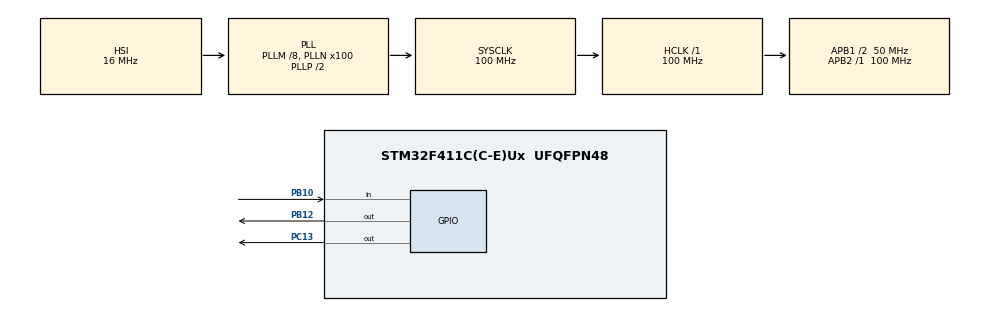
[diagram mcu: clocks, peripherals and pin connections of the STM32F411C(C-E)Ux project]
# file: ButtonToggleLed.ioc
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Mcu.Family=STM32F4
Mcu.Name=STM32F411C(C-E)Ux
Mcu.Package=UFQFPN48
NVIC.PriorityGroup=NVIC_PRIORITYGROUP_4
PA13.Mode=Serial_Wire
PA13.Signal=SYS_JTMS-SWDIO
PA14.Mode=Serial_Wire
PA14.Signal=SYS_JTCK-SWCLK
PB10.GPIO_PuPd=GPIO_PULLDOWN
PB10.Signal=GPIO_Input
PB12.Signal=GPIO_Output
PC13-ANTI_TAMP.Signal=GPIO_Output
PH0\ -\ OSC_IN.Mode=HSE-External-Oscillator
PH0\ -\ OSC_IN.Signal=RCC_OSC_IN
PH1\ -\ OSC_OUT.Mode=HSE-External-Oscillator
PH1\ -\ OSC_OUT.Signal=RCC_OSC_OUT
ProjectManager.HeapSize=0x200
ProjectManager.StackSize=0x400
ProjectManager.TargetToolchain=STM32CubeIDE
RCC.48MHZClocksFreq_Value=50000000
RCC.AHBFreq_Value=100000000
RCC.APB1CLKDivider=RCC_HCLK_DIV2
RCC.APB1Freq_Value=50000000
RCC.APB1TimFreq_Value=100000000
RCC.APB2Freq_Value=100000000
RCC.APB2TimFreq_Value=100000000
RCC.CortexFreq_Value=100000000
RCC.HCLKFreq_Value=100000000
RCC.HSE_VALUE=25000000
RCC.HSI_VALUE=16000000
RCC.LSE_VALUE=32768
RCC.PLLM=8
RCC.PLLN=100
RCC.SYSCLKFreq_VALUE=100000000
RCC.SYSCLKSource=RCC_SYSCLKSOURCE_PLLCLK
RCC.VCOOutputFreq_Value=200000000
board=custom

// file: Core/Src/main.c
/* USER CODE BEGIN Header */
/**
  ******************************************************************************
  * @file           : main.c
  * @brief          : Main program body
  ******************************************************************************
  * @attention
  *
  * Copyright (c) 2025 STMicroelectronics.
  * All rights reserved.
  *
  * This software is licensed under terms that can be found in the LICENSE file
  * in the root directory of this software component.
  * If no LICENSE file comes with this software, it is provided AS-IS.
  *
  ******************************************************************************
  */
/* USER CODE END Header */
#include "main.h"

/* USER CODE BEGIN PV */
uint8_t buttonState = 0;
uint8_t lastButtonState = 0;
uint32_t lastButtonPress = 0;
uint32_t buttonPressDuration = 0;
const uint32_t debounceDelay = 50; // 50ms para anti-rebote
const uint32_t longPressThreshold = 1000; // 1000ms = 1s para pulsación larga
/* USER CODE END PV */

void SystemClock_Config(void);
static void MX_GPIO_Init(void);

int main(void)
{

  /* MCU Configuration--------------------------------------------------------*/

  /* Reset of all peripherals, Initializes the Flash interface and the Systick. */
  HAL_Init();

  /* Configure the system clock */
  SystemClock_Config();

  /* Initialize all configured peripherals */
  MX_GPIO_Init();

  /* Infinite loop */
  /* USER CODE BEGIN WHILE */
  while (1)
  {
	  // =====================================================
	  // Lectura básica
	  // =====================================================
	  /*
	  if(HAL_GPIO_ReadPin(GPIOB, GPIO_PIN_10) == GPIO_PIN_SET)
	  {
		  HAL_GPIO_TogglePin(GPIOC, GPIO_PIN_13);
		  HAL_Delay(250); // Pequeño delay para evitar múltiples toggles
	  }
	  */
	  // =====================================================

	  // =====================================================
	  // Anti-Rebote
	  // =====================================================
	  /*
	    if(HAL_GPIO_ReadPin(GPIOB, GPIO_PIN_10) == GPIO_PIN_SET)
	    {
	        // Verificar anti-rebote
	        if(HAL_GetTick() - lastButtonPress > debounceDelay)
	        {
	            HAL_GPIO_TogglePin(GPIOC, GPIO_PIN_13);
	            lastButtonPress = HAL_GetTick();
	        }
	    }

	    // Pequeño delay para no saturar la CPU
	    HAL_Delay(debounceDelay);
	    */
	  // =====================================================

	  // =====================================================
	  // Detección de flanco de subida con anti-rebote
	  // =====================================================
	  /*
	  // Leer el estado actual del botón
	  buttonState = HAL_GPIO_ReadPin(GPIOB, GPIO_PIN_10);

	  // Detectar flanco de subida (cuando el botón se presiona)
	  if(buttonState == GPIO_PIN_SET && lastButtonState == GPIO_PIN_RESET)
	  {
	      // Anti-rebote: verificar que el botón sigue presionado después del delay
	      HAL_Delay(debounceDelay);
	      if(HAL_GPIO_ReadPin(GPIOB, GPIO_PIN_10) == GPIO_PIN_SET)
	      {
	          HAL_GPIO_TogglePin(GPIOC, GPIO_PIN_13);
	      }
	  }
	  lastButtonState = buttonState;

	  // Pequeño delay para reducir carga de CPU
	  HAL_Delay(10);
	  */
	  // =====================================================

	  // =====================================================
	  // Detección pulsación larga
	  // =====================================================
	  // Leer el estado actual del botón
	  buttonState = HAL_GPIO_ReadPin(GPIOB, GPIO_PIN_10);

	  // Detectar flanco de subida (botón presionado)
	  if(buttonState == GPIO_PIN_SET && lastButtonState == GPIO_PIN_RESET)
	  {
	      // Registrar el momento en que se presiona el botón
	      lastButtonPress = HAL_GetTick();

	      // Anti-rebote
	      HAL_Delay(debounceDelay);

	  }

	  // Detectar flanco de bajada (botón liberado)
	  if(buttonState == GPIO_PIN_RESET && lastButtonState == GPIO_PIN_SET)
	  {
		  // Calcular la duración de la pulsación
		  buttonPressDuration = HAL_GetTick() - lastButtonPress;

		  // Determinar si fue pulsación corta o larga
		  if(buttonPressDuration < longPressThreshold)
		  {
			  // PULSACIÓN CORTA: Cambiar estado del LED
			  HAL_GPIO_TogglePin(GPIOC, GPIO_PIN_13);
		  }
		  else
		  {
			  // PULSACIÓN LARGA: Realizar acción diferente
			  HAL_GPIO_TogglePin(GPIOB, GPIO_PIN_12);
		  }
	  }

	  // Actualizar el estado anterior del botón
	  lastButtonState = buttonState;

	  // Pequeño delay para reducir carga de CPU
	  HAL_Delay(10);
    /* USER CODE END WHILE */

  }
}

void SystemClock_Config(void)
{
  RCC_OscInitTypeDef RCC_OscInitStruct = {0};
  RCC_ClkInitTypeDef RCC_ClkInitStruct = {0};

  /** Configure the main internal regulator output voltage
  */
  __HAL_RCC_PWR_CLK_ENABLE();
  __HAL_PWR_VOLTAGESCALING_CONFIG(PWR_REGULATOR_VOLTAGE_SCALE1);

  /** Initializes the RCC Oscillators according to the specified parameters
  * in the RCC_OscInitTypeDef structure.
  */
  RCC_OscInitStruct.OscillatorType = RCC_OSCILLATORTYPE_HSI;
  RCC_OscInitStruct.HSIState = RCC_HSI_ON;
  RCC_OscInitStruct.HSICalibrationValue = RCC_HSICALIBRATION_DEFAULT;
  RCC_OscInitStruct.PLL.PLLState = RCC_PLL_ON;
  RCC_OscInitStruct.PLL.PLLSource = RCC_PLLSOURCE_HSI;
  RCC_OscInitStruct.PLL.PLLM = 8;
  RCC_OscInitStruct.PLL.PLLN = 100;
  RCC_OscInitStruct.PLL.PLLP = RCC_PLLP_DIV2;
  RCC_OscInitStruct.PLL.PLLQ = 4;
  if (HAL_RCC_OscConfig(&RCC_OscInitStruct) != HAL_OK)
  {
    Error_Handler();
  }

  /** Initializes the CPU, AHB and APB buses clocks
  */
  RCC_ClkInitStruct.ClockType = RCC_CLOCKTYPE_HCLK|RCC_CLOCKTYPE_SYSCLK
                              |RCC_CLOCKTYPE_PCLK1|RCC_CLOCKTYPE_PCLK2;
  RCC_ClkInitStruct.SYSCLKSource = RCC_SYSCLKSOURCE_PLLCLK;
  RCC_ClkInitStruct.AHBCLKDivider = RCC_SYSCLK_DIV1;
  RCC_ClkInitStruct.APB1CLKDivider = RCC_HCLK_DIV2;
  RCC_ClkInitStruct.APB2CLKDivider = RCC_HCLK_DIV1;

  if (HAL_RCC_ClockConfig(&RCC_ClkInitStruct, FLASH_LATENCY_3) != HAL_OK)
  {
    Error_Handler();
  }
}

static void MX_GPIO_Init(void)
{
  GPIO_InitTypeDef GPIO_InitStruct = {0};

  /* GPIO Ports Clock Enable */
  __HAL_RCC_GPIOC_CLK_ENABLE();
  __HAL_RCC_GPIOH_CLK_ENABLE();
  __HAL_RCC_GPIOB_CLK_ENABLE();
  __HAL_RCC_GPIOA_CLK_ENABLE();

  /*Configure GPIO pin Output Level */
  HAL_GPIO_WritePin(GPIOC, GPIO_PIN_13, GPIO_PIN_RESET);

  /*Configure GPIO pin Output Level */
  HAL_GPIO_WritePin(GPIOB, GPIO_PIN_12, GPIO_PIN_RESET);

  /*Configure GPIO pin : PC13 */
  GPIO_InitStruct.Pin = GPIO_PIN_13;
  GPIO_InitStruct.Mode = GPIO_MODE_OUTPUT_PP;
  GPIO_InitStruct.Pull = GPIO_NOPULL;
  GPIO_InitStruct.Speed = GPIO_SPEED_FREQ_LOW;
  HAL_GPIO_Init(GPIOC, &GPIO_InitStruct);

  /*Configure GPIO pin : PB10 */
  GPIO_InitStruct.Pin = GPIO_PIN_10;
  GPIO_InitStruct.Mode = GPIO_MODE_INPUT;
  GPIO_InitStruct.Pull = GPIO_PULLDOWN;
  HAL_GPIO_Init(GPIOB, &GPIO_InitStruct);

  /*Configure GPIO pin : PB12 */
  GPIO_InitStruct.Pin = GPIO_PIN_12;
  GPIO_InitStruct.Mode = GPIO_MODE_OUTPUT_PP;
  GPIO_InitStruct.Pull = GPIO_NOPULL;
  GPIO_InitStruct.Speed = GPIO_SPEED_FREQ_LOW;
  HAL_GPIO_Init(GPIOB, &GPIO_InitStruct);

}

void Error_Handler(void)
{
  __disable_irq();
  while (1)
  {
  }
}
